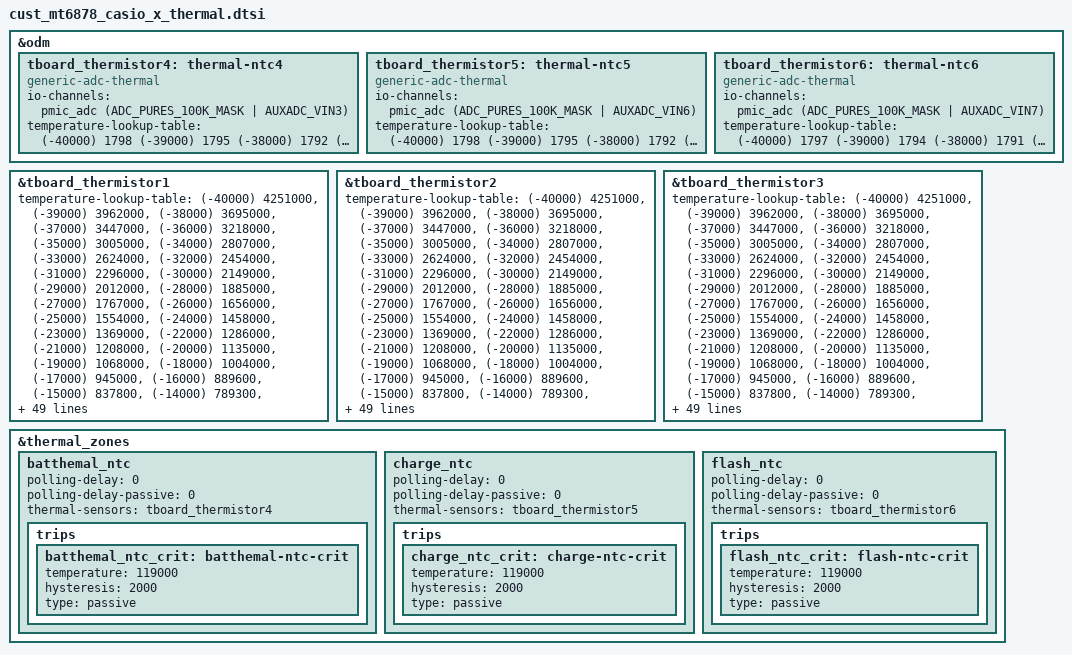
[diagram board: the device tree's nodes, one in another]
// SPDX-License-Identifier: GPL-2.0-only
/*
* Copyright (C) 2022 Oplus. All rights reserved.
*/

#include <dt-bindings/iio/mt635x-auxadc.h>

&odm {

	tboard_thermistor4: thermal-ntc4 {
		compatible = "generic-adc-thermal";
		#thermal-sensor-cells = <0>;
		io-channels = <&pmic_adc (ADC_PURES_100K_MASK | AUXADC_VIN3)>;
		io-channel-names = "sensor-channel";
		temperature-lookup-table = <
			(-40000) 1798
			(-39000) 1795
			(-38000) 1792
			(-37000) 1788
			(-36000) 1785
			(-35000) 1781
			(-34000) 1777
			(-33000) 1772
			(-32000) 1768
			(-31000) 1763
			(-30000) 1758
			(-29000) 1753
			(-28000) 1747
			(-27000) 1741
			(-26000) 1735
			(-25000) 1729
			(-24000) 1722
			(-23000) 1715
			(-22000) 1707
			(-21000) 1699
			(-20000) 1691
			(-19000) 1682
			(-18000) 1673
			(-17000) 1664
			(-16000) 1654
			(-15000) 1644
			(-14000) 1633
			(-13000) 1622
			(-12000) 1610
			(-11000) 1598
			(-10000) 1586
			(-9000) 1573
			(-8000) 1560
			(-7000) 1546
			(-6000) 1531
			(-5000) 1517
			(-4000) 1501
			(-3000) 1486
			(-2000) 1470
			(-1000) 1453
			0 1436
			1000 1419
			2000 1401
			3000 1383
			4000 1364
			5000 1345
			6000 1326
			7000 1306
			8000 1286
			9000 1266
			10000 1245
			11000 1224
			12000 1203
			13000 1182
			14000 1161
			15000 1139
			16000 1117
			17000 1096
			18000 1074
			19000 1052
			20000 1029
			21000 1007
			22000 986
			23000 964
			24000 942
			25000 920
			26000 898
			27000 877
			28000 856
			29000 834
			30000 813
			31000 793
			32000 772
			33000 752
			34000 732
			35000 712
			36000 693
			37000 674
			38000 655
			39000 637
			40000 619
			41000 601
			42000 584
			43000 567
			44000 550
			45000 534
			46000 518
			47000 503
			48000 488
			49000 473
			50000 459
			51000 445
			52000 431
			53000 418
			54000 405
			55000 392
			56000 380
			57000 368
			58000 357
			59000 345
			60000 335
			61000 324
			62000 314
			63000 304
			64000 294
			65000 285
			66000 276
			67000 267
			68000 259
			69000 251
			70000 243
			71000 235
			72000 227
			73000 220
			74000 213
			75000 206
			76000 200
			77000 194
			78000 188
			79000 182
			80000 176
			81000 170
			82000 165
			83000 160
			84000 155
			85000 150
			86000 146
			87000 141
			88000 137
			89000 132
			90000 128
			91000 124
			92000 121
			93000 117
			94000 113
			95000 110
			96000 107
			97000 103
			98000 100
			99000 97
			100000 94
			101000 92
			102000 89
			103000 86
			104000 84
			105000 81
			106000 79
			107000 77
			108000 74
			109000 72
			110000 70
			111000 68
			112000 66
			113000 64
			114000 63
			115000 61
			116000 59
			117000 57
			118000 56
			119000 54
			120000 53
			121000 51
			122000 50
			123000 49
			124000 47
			125000 46>;
	};

	tboard_thermistor5: thermal-ntc5 {
		compatible = "generic-adc-thermal";
		#thermal-sensor-cells = <0>;
		io-channels = <&pmic_adc (ADC_PURES_100K_MASK | AUXADC_VIN6)>;
		io-channel-names = "sensor-channel";
		temperature-lookup-table = <
			(-40000) 1798
			(-39000) 1795
			(-38000) 1792
			(-37000) 1788
			(-36000) 1785
			(-35000) 1781
			(-34000) 1777
			(-33000) 1772
			(-32000) 1768
			(-31000) 1763
			(-30000) 1758
			(-29000) 1753
			(-28000) 1747
			(-27000) 1741
			(-26000) 1735
			(-25000) 1729
			(-24000) 1722
			(-23000) 1715
			(-22000) 1707
			(-21000) 1699
			(-20000) 1691
			(-19000) 1682
			(-18000) 1673
			(-17000) 1664
			(-16000) 1654
			(-15000) 1644
			(-14000) 1633
			(-13000) 1622
			(-12000) 1610
			(-11000) 1598
			(-10000) 1586
			(-9000) 1573
			(-8000) 1560
			(-7000) 1546
			(-6000) 1531
			(-5000) 1517
			(-4000) 1501
			(-3000) 1486
			(-2000) 1470
			(-1000) 1453
			0 1436
			1000 1419
			2000 1401
			3000 1383
			4000 1364
			5000 1345
			6000 1326
			7000 1306
			8000 1286
			9000 1266
			10000 1245
			11000 1224
			12000 1203
			13000 1182
			14000 1161
			15000 1139
			16000 1117
			17000 1096
			18000 1074
			19000 1052
			20000 1029
			21000 1007
			22000 986
			23000 964
			24000 942
			25000 920
			26000 898
			27000 877
			28000 856
			29000 834
			30000 813
			31000 793
			32000 772
			33000 752
			34000 732
			35000 712
			36000 693
			37000 674
			38000 655
			39000 637
			40000 619
			41000 601
			42000 584
			43000 567
			44000 550
			45000 534
			46000 518
			47000 503
			48000 488
			49000 473
			50000 459
			51000 445
			52000 431
			53000 418
			54000 405
			55000 392
			56000 380
			57000 368
			58000 357
			59000 345
			60000 335
			61000 324
			62000 314
			63000 304
			64000 294
			65000 285
			66000 276
			67000 267
			68000 259
			69000 251
			70000 243
			71000 235
			72000 227
			73000 220
			74000 213
			75000 206
			76000 200
			77000 194
			78000 188
			79000 182
			80000 176
			81000 170
			82000 165
			83000 160
			84000 155
			85000 150
			86000 146
			87000 141
			88000 137
			89000 132
			90000 128
			91000 124
			92000 121
			93000 117
			94000 113
			95000 110
			96000 107
			97000 103
			98000 100
			99000 97
			100000 94
			101000 92
			102000 89
			103000 86
			104000 84
			105000 81
			106000 79
			107000 77
			108000 74
			109000 72
			110000 70
			111000 68
			112000 66
			113000 64
			114000 63
			115000 61
			116000 59
			117000 57
			118000 56
			119000 54
			120000 53
			121000 51
			122000 50
			123000 49
			124000 47
			125000 46>;
	};

	tboard_thermistor6: thermal-ntc6 {
		compatible = "generic-adc-thermal";
		#thermal-sensor-cells = <0>;
		io-channels = <&pmic_adc (ADC_PURES_100K_MASK | AUXADC_VIN7)>;
		io-channel-names = "sensor-channel";
		temperature-lookup-table = <
			(-40000) 1797
			(-39000) 1794
			(-38000) 1791
			(-37000) 1788
			(-36000) 1784
			(-35000) 1780
			(-34000) 1776
			(-33000) 1772
			(-32000) 1767
			(-31000) 1762
			(-30000) 1757
			(-29000) 1752
			(-28000) 1746
			(-27000) 1741
			(-26000) 1734
			(-25000) 1728
			(-24000) 1721
			(-23000) 1714
			(-22000) 1706
			(-21000) 1698
			(-20000) 1690
			(-19000) 1681
			(-18000) 1672
			(-17000) 1662
			(-16000) 1652
			(-15000) 1642
			(-14000) 1631
			(-13000) 1620
			(-12000) 1608
			(-11000) 1596
			(-10000) 1584
			(-9000) 1571
			(-8000) 1557
			(-7000) 1543
			(-6000) 1529
			(-5000) 1514
			(-4000) 1499
			(-3000) 1483
			(-2000) 1467
			(-1000) 1450
			0 1433
			1000 1416
			2000 1398
			3000 1379
			4000 1361
			5000 1342
			6000 1322
			7000 1302
			8000 1282
			9000 1262
			10000 1241
			11000 1220
			12000 1199
			13000 1178
			14000 1157
			15000 1135
			16000 1113
			17000 1091
			18000 1069
			19000 1047
			20000 1025
			21000 1003
			22000 981
			23000 959
			24000 937
			25000 915
			26000 894
			27000 872
			28000 851
			29000 830
			30000 809
			31000 788
			32000 768
			33000 748
			34000 728
			35000 708
			36000 689
			37000 670
			38000 651
			39000 633
			40000 615
			41000 597
			42000 580
			43000 563
			44000 546
			45000 530
			46000 515
			47000 499
			48000 484
			49000 469
			50000 455
			51000 441
			52000 428
			53000 414
			54000 402
			55000 389
			56000 377
			57000 365
			58000 354
			59000 343
			60000 332
			61000 321
			62000 311
			63000 301
			64000 292
			65000 283
			66000 274
			67000 265
			68000 256
			69000 248
			70000 240
			71000 233
			72000 225
			73000 218
			74000 211
			75000 205
			76000 198
			77000 192
			78000 186
			79000 180
			80000 174
			81000 169
			82000 164
			83000 159
			84000 154
			85000 149
			86000 144
			87000 140
			88000 135
			89000 131
			90000 127
			91000 123
			92000 120
			93000 116
			94000 112
			95000 109
			96000 106
			97000 102
			98000 99
			99000 96
			100000 94
			101000 91
			102000 88
			103000 85
			104000 83
			105000 81
			106000 78
			107000 76
			108000 74
			109000 72
			110000 70
			111000 68
			112000 66
			113000 64
			114000 62
			115000 60
			116000 58
			117000 57
			118000 55
			119000 54
			120000 52
			121000 51
			122000 49
			123000 48
			124000 47
			125000 46>;
	};
};

&tboard_thermistor1 {
		temperature-lookup-table =
			<(-40000) 4251000>,
			<(-39000) 3962000>,
			<(-38000) 3695000>,
			<(-37000) 3447000>,
			<(-36000) 3218000>,
			<(-35000) 3005000>,
			<(-34000) 2807000>,
			<(-33000) 2624000>,
			<(-32000) 2454000>,
			<(-31000) 2296000>,
			<(-30000) 2149000>,
			<(-29000) 2012000>,
			<(-28000) 1885000>,
			<(-27000) 1767000>,
			<(-26000) 1656000>,
			<(-25000) 1554000>,
			<(-24000) 1458000>,
			<(-23000) 1369000>,
			<(-22000) 1286000>,
			<(-21000) 1208000>,
			<(-20000) 1135000>,
			<(-19000) 1068000>,
			<(-18000) 1004000>,
			<(-17000) 945000>,
			<(-16000) 889600>,
			<(-15000) 837800>,
			<(-14000) 789300>,
			<(-13000) 743900>,
			<(-12000) 701300>,
			<(-11000) 661500>,
			<(-10000) 624100>,
			<(-9000) 589000>,
			<(-8000) 556200>,
			<(-7000) 525300>,
			<(-6000) 496300>,
			<(-5000) 469100>,
			<(-4000) 443500>,
			<(-3000) 419500>,
			<(-2000) 396900>,
			<(-1000) 375600>,
			<0 355600>,
			<1000 336800>,
			<2000 319100>,
			<3000 302400>,
			<4000 286700>,
			<5000 271800>,
			<6000 257800>,
			<7000 244700>,
			<8000 232200>,
			<9000 220500>,
			<10000 209400>,
			<11000 198900>,
			<12000 189000>,
			<13000 179700>,
			<14000 170900>,
			<15000 162500>,
			<16000 154600>,
			<17000 147200>,
			<18000 140100>,
			<19000 133400>,
			<20000 127000>,
			<21000 121000>,
			<22000 115400>,
			<23000 110000>,
			<24000 104800>,
			<25000 100000>,
			<26000 95400>,
			<27000 91040>,
			<28000 86900>,
			<29000 82970>,
			<30000 79230>,
			<31000 75690>,
			<32000 72320>,
			<33000 69120>,
			<34000 66070>,
			<35000 63180>,
			<36000 60420>,
			<37000 57810>,
			<38000 55310>,
			<39000 52940>,
			<40000 50680>,
			<41000 48530>,
			<42000 46490>,
			<43000 44530>,
			<44000 42670>,
			<45000 40900>,
			<46000 39210>,
			<47000 37600>,
			<48000 36060>,
			<49000 34600>,
			<50000 33190>,
			<51000 31860>,
			<52000 30580>,
			<53000 29360>,
			<54000 28200>,
			<55000 27090>,
			<56000 26030>,
			<57000 25010>,
			<58000 24040>,
			<59000 23110>,
			<60000 22220>,
			<61000 21370>,
			<62000 20560>,
			<63000 19780>,
			<64000 19040>,
			<65000 18320>,
			<66000 17640>,
			<67000 16990>,
			<68000 16360>,
			<69000 15760>,
			<70000 15180>,
			<71000 14630>,
			<72000 14100>,
			<73000 13600>,
			<74000 13110>,
			<75000 12640>,
			<76000 12190>,
			<77000 11760>,
			<78000 11350>,
			<79000 10960>,
			<80000 10580>,
			<81000 10210>,
			<82000 9859>,
			<83000 9522>,
			<84000 9198>,
			<85000 8887>,
			<86000 8587>,
			<87000 8299>,
			<88000 8022>,
			<89000 7756>,
			<90000 7500>,
			<91000 7254>,
			<92000 7016>,
			<93000 6788>,
			<94000 6568>,
			<95000 6357>,
			<96000 6153>,
			<97000 5957>,
			<98000 5768>,
			<99000 5586>,
			<100000 5410>,
			<101000 5241>,
			<102000 5078>,
			<103000 4921>,
			<104000 4769>,
			<105000 4623>,
			<106000 4482>,
			<107000 4346>,
			<108000 4215>,
			<109000 4088>,
			<110000 3966>,
			<111000 3848>,
			<112000 3734>,
			<113000 3624>,
			<114000 3518>,
			<115000 3415>,
			<116000 3316>,
			<117000 3220>,
			<118000 3128>,
			<119000 3038>,
			<120000 2952>,
			<121000 2868>,
			<122000 2787>,
			<123000 2709>,
			<124000 2634>,
			<125000 2561>;
};

&tboard_thermistor2 {

		temperature-lookup-table =
			<(-40000) 4251000>,
			<(-39000) 3962000>,
			<(-38000) 3695000>,
			<(-37000) 3447000>,
			<(-36000) 3218000>,
			<(-35000) 3005000>,
			<(-34000) 2807000>,
			<(-33000) 2624000>,
			<(-32000) 2454000>,
			<(-31000) 2296000>,
			<(-30000) 2149000>,
			<(-29000) 2012000>,
			<(-28000) 1885000>,
			<(-27000) 1767000>,
			<(-26000) 1656000>,
			<(-25000) 1554000>,
			<(-24000) 1458000>,
			<(-23000) 1369000>,
			<(-22000) 1286000>,
			<(-21000) 1208000>,
			<(-20000) 1135000>,
			<(-19000) 1068000>,
			<(-18000) 1004000>,
			<(-17000) 945000>,
			<(-16000) 889600>,
			<(-15000) 837800>,
			<(-14000) 789300>,
			<(-13000) 743900>,
			<(-12000) 701300>,
			<(-11000) 661500>,
			<(-10000) 624100>,
			<(-9000) 589000>,
			<(-8000) 556200>,
			<(-7000) 525300>,
			<(-6000) 496300>,
			<(-5000) 469100>,
			<(-4000) 443500>,
			<(-3000) 419500>,
			<(-2000) 396900>,
			<(-1000) 375600>,
			<0 355600>,
			<1000 336800>,
			<2000 319100>,
			<3000 302400>,
			<4000 286700>,
			<5000 271800>,
			<6000 257800>,
			<7000 244700>,
			<8000 232200>,
			<9000 220500>,
			<10000 209400>,
			<11000 198900>,
			<12000 189000>,
			<13000 179700>,
			<14000 170900>,
			<15000 162500>,
			<16000 154600>,
			<17000 147200>,
			<18000 140100>,
			<19000 133400>,
			<20000 127000>,
			<21000 121000>,
			<22000 115400>,
			<23000 110000>,
			<24000 104800>,
			<25000 100000>,
			<26000 95400>,
			<27000 91040>,
			<28000 86900>,
			<29000 82970>,
			<30000 79230>,
			<31000 75690>,
			<32000 72320>,
			<33000 69120>,
			<34000 66070>,
			<35000 63180>,
			<36000 60420>,
			<37000 57810>,
			<38000 55310>,
			<39000 52940>,
			<40000 50680>,
			<41000 48530>,
			<42000 46490>,
			<43000 44530>,
			<44000 42670>,
			<45000 40900>,
			<46000 39210>,
			<47000 37600>,
			<48000 36060>,
			<49000 34600>,
			<50000 33190>,
			<51000 31860>,
			<52000 30580>,
			<53000 29360>,
			<54000 28200>,
			<55000 27090>,
			<56000 26030>,
			<57000 25010>,
			<58000 24040>,
			<59000 23110>,
			<60000 22220>,
			<61000 21370>,
			<62000 20560>,
			<63000 19780>,
			<64000 19040>,
			<65000 18320>,
			<66000 17640>,
			<67000 16990>,
			<68000 16360>,
			<69000 15760>,
			<70000 15180>,
			<71000 14630>,
			<72000 14100>,
			<73000 13600>,
			<74000 13110>,
			<75000 12640>,
			<76000 12190>,
			<77000 11760>,
			<78000 11350>,
			<79000 10960>,
			<80000 10580>,
			<81000 10210>,
			<82000 9859>,
			<83000 9522>,
			<84000 9198>,
			<85000 8887>,
			<86000 8587>,
			<87000 8299>,
			<88000 8022>,
			<89000 7756>,
			<90000 7500>,
			<91000 7254>,
			<92000 7016>,
			<93000 6788>,
			<94000 6568>,
			<95000 6357>,
			<96000 6153>,
			<97000 5957>,
			<98000 5768>,
			<99000 5586>,
			<100000 5410>,
			<101000 5241>,
			<102000 5078>,
			<103000 4921>,
			<104000 4769>,
			<105000 4623>,
			<106000 4482>,
			<107000 4346>,
			<108000 4215>,
			<109000 4088>,
			<110000 3966>,
			<111000 3848>,
			<112000 3734>,
			<113000 3624>,
			<114000 3518>,
			<115000 3415>,
			<116000 3316>,
			<117000 3220>,
			<118000 3128>,
			<119000 3038>,
			<120000 2952>,
			<121000 2868>,
			<122000 2787>,
			<123000 2709>,
			<124000 2634>,
			<125000 2561>;
};

&tboard_thermistor3 {
		temperature-lookup-table =
			<(-40000) 4251000>,
			<(-39000) 3962000>,
			<(-38000) 3695000>,
			<(-37000) 3447000>,
			<(-36000) 3218000>,
			<(-35000) 3005000>,
			<(-34000) 2807000>,
			<(-33000) 2624000>,
			<(-32000) 2454000>,
			<(-31000) 2296000>,
			<(-30000) 2149000>,
			<(-29000) 2012000>,
			<(-28000) 1885000>,
			<(-27000) 1767000>,
			<(-26000) 1656000>,
			<(-25000) 1554000>,
			<(-24000) 1458000>,
			<(-23000) 1369000>,
			<(-22000) 1286000>,
			<(-21000) 1208000>,
			<(-20000) 1135000>,
			<(-19000) 1068000>,
			<(-18000) 1004000>,
			<(-17000) 945000>,
			<(-16000) 889600>,
			<(-15000) 837800>,
			<(-14000) 789300>,
			<(-13000) 743900>,
			<(-12000) 701300>,
			<(-11000) 661500>,
			<(-10000) 624100>,
			<(-9000) 589000>,
			<(-8000) 556200>,
			<(-7000) 525300>,
			<(-6000) 496300>,
			<(-5000) 469100>,
			<(-4000) 443500>,
			<(-3000) 419500>,
			<(-2000) 396900>,
			<(-1000) 375600>,
			<0 355600>,
			<1000 336800>,
			<2000 319100>,
			<3000 302400>,
			<4000 286700>,
			<5000 271800>,
			<6000 257800>,
			<7000 244700>,
			<8000 232200>,
			<9000 220500>,
			<10000 209400>,
			<11000 198900>,
			<12000 189000>,
			<13000 179700>,
			<14000 170900>,
			<15000 162500>,
			<16000 154600>,
			<17000 147200>,
			<18000 140100>,
			<19000 133400>,
			<20000 127000>,
			<21000 121000>,
			<22000 115400>,
			<23000 110000>,
			<24000 104800>,
			<25000 100000>,
			<26000 95400>,
			<27000 91040>,
			<28000 86900>,
			<29000 82970>,
			<30000 79230>,
			<31000 75690>,
			<32000 72320>,
			<33000 69120>,
			<34000 66070>,
			<35000 63180>,
			<36000 60420>,
			<37000 57810>,
			<38000 55310>,
			<39000 52940>,
			<40000 50680>,
			<41000 48530>,
			<42000 46490>,
			<43000 44530>,
			<44000 42670>,
			<45000 40900>,
			<46000 39210>,
			<47000 37600>,
			<48000 36060>,
			<49000 34600>,
			<50000 33190>,
			<51000 31860>,
			<52000 30580>,
			<53000 29360>,
			<54000 28200>,
			<55000 27090>,
			<56000 26030>,
			<57000 25010>,
			<58000 24040>,
			<59000 23110>,
			<60000 22220>,
			<61000 21370>,
			<62000 20560>,
			<63000 19780>,
			<64000 19040>,
			<65000 18320>,
			<66000 17640>,
			<67000 16990>,
			<68000 16360>,
			<69000 15760>,
			<70000 15180>,
			<71000 14630>,
			<72000 14100>,
			<73000 13600>,
			<74000 13110>,
			<75000 12640>,
			<76000 12190>,
			<77000 11760>,
			<78000 11350>,
			<79000 10960>,
			<80000 10580>,
			<81000 10210>,
			<82000 9859>,
			<83000 9522>,
			<84000 9198>,
			<85000 8887>,
			<86000 8587>,
			<87000 8299>,
			<88000 8022>,
			<89000 7756>,
			<90000 7500>,
			<91000 7254>,
			<92000 7016>,
			<93000 6788>,
			<94000 6568>,
			<95000 6357>,
			<96000 6153>,
			<97000 5957>,
			<98000 5768>,
			<99000 5586>,
			<100000 5410>,
			<101000 5241>,
			<102000 5078>,
			<103000 4921>,
			<104000 4769>,
			<105000 4623>,
			<106000 4482>,
			<107000 4346>,
			<108000 4215>,
			<109000 4088>,
			<110000 3966>,
			<111000 3848>,
			<112000 3734>,
			<113000 3624>,
			<114000 3518>,
			<115000 3415>,
			<116000 3316>,
			<117000 3220>,
			<118000 3128>,
			<119000 3038>,
			<120000 2952>,
			<121000 2868>,
			<122000 2787>,
			<123000 2709>,
			<124000 2634>,
			<125000 2561>;
};

&thermal_zones
{
	batthemal_ntc: batthemal_ntc {
		polling-delay = <0>; /* milliseconds */
		polling-delay-passive = <0>; /* milliseconds */
		thermal-sensors = <&tboard_thermistor4>;
        trips {
				batthemal_ntc_crit: batthemal-ntc-crit {
					temperature = <119000>;
					hysteresis = <2000>;
					type = "passive";
				};
			};
	};

	charge_ntc: charge_ntc {
		polling-delay = <0>; /* milliseconds */
		polling-delay-passive = <0>; /* milliseconds */
		thermal-sensors = <&tboard_thermistor5>;
        trips {
				charge_ntc_crit: charge-ntc-crit {
					temperature = <119000>;
					hysteresis = <2000>;
					type = "passive";
				};
			};
	};

	flash_ntc: flash_ntc {
		polling-delay = <0>; /* milliseconds */
		polling-delay-passive = <0>; /* milliseconds */
		thermal-sensors = <&tboard_thermistor6>;
        trips {
				flash_ntc_crit: flash-ntc-crit {
					temperature = <119000>;
					hysteresis = <2000>;
					type = "passive";
				};
			};
	};

};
